# MKV31F51212 register map
Vendor: Freescale Semiconductor, Inc.; Series: Kinetis_V; File version: 1.6
CPU: CM4 r0p1, little endian, no MPU, FPU, VTOR, 4 interrupt priority bits
Registers are 32-bit, read-write, reset 0x0 unless marked. A register's access mark holds for its fields unless they carry their own. Offsets are from the block's base; [hi:lo] are bit positions; {n}, {i} and the like mark numbered series.

## PTA — General Purpose Input/Output
Base 0x400FF000; register names take the prefix GPIOA_
0x00 PDOR — Port Data Output Register
  [31:0] PDO — Port Data Output
    0=Logic level 0 is driven on pin, provided pin is configured for general-purpose output; 1=Logic level 1 is driven on pin, provided pin is configured for general-purpose output
0x04 PSOR wo — Port Set Output Register
  [31:0] PTSO — Port Set Output
    0=Corresponding bit in PDORn does not change; 1=Corresponding bit in PDORn is set to logic 1
0x08 PCOR wo — Port Clear Output Register
  [31:0] PTCO — Port Clear Output
    0=Corresponding bit in PDORn does not change; 1=Corresponding bit in PDORn is cleared to logic 0
0x0C PTOR wo — Port Toggle Output Register
  [31:0] PTTO — Port Toggle Output
    0=Corresponding bit in PDORn does not change; 1=Corresponding bit in PDORn is set to the inverse of its existing logic state
0x10 PDIR ro — Port Data Input Register
  [31:0] PDI — Port Data Input
    0=Pin logic level is logic 0, or is not configured for use by digital function; 1=Pin logic level is logic 1
0x14 PDDR — Port Data Direction Register
  [31:0] PDD — Port Data Direction
    0=Pin is configured as general-purpose input, for the GPIO function; 1=Pin is configured as general-purpose output, for the GPIO function

## PTB — General Purpose Input/Output
Base 0x400FF040; register names take the prefix GPIOB_
Registers as PTA.

## PTC — General Purpose Input/Output
Base 0x400FF080; register names take the prefix GPIOC_
Registers as PTA; these are added or differ:
0x08 PCOR wo — Port Clear Output Register
  [31:0] PTCO — Port Clear Output
    0=Corresponding bit in PDORn does not change; 1=Corresponding bit in PDORn is cleared to logic 0

## PTD — General Purpose Input/Output
Base 0x400FF0C0; register names take the prefix GPIOD_
Registers as PTA.

## PTE — General Purpose Input/Output
Base 0x400FF100; register names take the prefix GPIOE_
Registers as PTA.

## SysTick — System timer
Base 0xE000E010; register names take the prefix SYST_
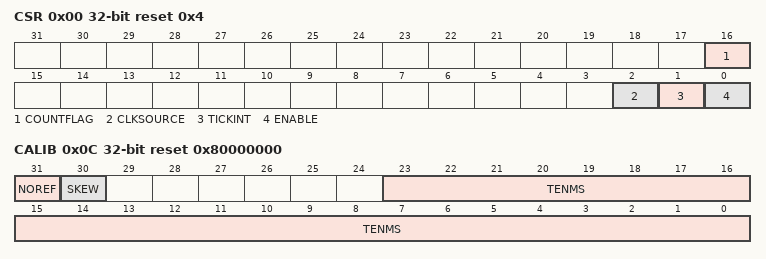
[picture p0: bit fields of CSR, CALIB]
0x00 CSR reset 0x4 — SysTick Control and Status Register
  [16] COUNTFLAG
  [2] CLKSOURCE
    0=external clock; 1=processor clock
  [1] TICKINT
    0=counting down to 0 does not assert the SysTick exception request; 1=counting down to 0 asserts the SysTick exception request
  [0] ENABLE
    0=counter disabled; 1=counter enabled
0x04 RVR — SysTick Reload Value Register
  [23:0] RELOAD — Value to load into the SysTick Current Value Register when the counter reaches 0
0x08 CVR — SysTick Current Value Register
  [23:0] CURRENT — Current value at the time the register is accessed
0x0C CALIB ro reset 0x80000000 — SysTick Calibration Value Register
  [31] NOREF
    0=The reference clock is provided; 1=The reference clock is not provided
  [30] SKEW
    0=10ms calibration value is exact; 1=10ms calibration value is inexact, because of the clock frequency
  [23:0] TENMS — Reload value to use for 10ms timing

## NVIC — Nested Vectored Interrupt Controller
Base 0xE000E100
{0x0+4i} NVICISER{i} (i=0..3) — Interrupt Set Enable Register n
  [31:0] SETENA — Interrupt set enable bits
{0x80+4i} NVICICER{i} (i=0..3) — Interrupt Clear Enable Register n
  [31:0] CLRENA — Interrupt clear-enable bits
{0x100+4i} NVICISPR{i} (i=0..3) — Interrupt Set Pending Register n
  [31:0] SETPEND — Interrupt set-pending bits
{0x180+4i} NVICICPR{i} (i=0..3) — Interrupt Clear Pending Register n
  [31:0] CLRPEND — Interrupt clear-pending bits
{0x200+4i} NVICIABR{i} (i=0..3) — Interrupt Active bit Register n
  [31:0] ACTIVE — Interrupt active flags
{0x300+i} NVICIP{i} 8-bit (i=0..105) — Interrupt Priority Register n
  [7:0] PRI{i} — Priority of interrupt {i}
0xE00 NVICSTIR — Software Trigger Interrupt Register
  [8:0] INTID — Interrupt ID of the interrupt to trigger, in the range 0-239. For example, a value of 0x03 specifies interrupt IRQ3.

## MCM — Core Platform Miscellaneous Control Module
Base 0xE0080000; register names take the prefix MCM_
0x08 PLASC 16-bit ro reset 0x1F — Crossbar Switch (AXBS) Slave Configuration
  [7:0] ASC — Each bit in the ASC field indicates whether there is a corresponding connection to the crossbar switch's slave input port.
    0=A bus slave connection to AXBS input port n is absent; 1=A bus slave connection to AXBS input port n is present
0x0A PLAMC 16-bit ro reset 0x17 — Crossbar Switch (AXBS) Master Configuration
  [7:0] AMC — Each bit in the AMC field indicates whether there is a corresponding connection to the AXBS master input port.
    0=A bus master connection to AXBS input port n is absent; 1=A bus master connection to AXBS input port n is present
0x0C PLACR — Crossbar Switch (AXBS) Control Register
  [9] ARB — Arbitration select
    0=Fixed-priority arbitration for the crossbar masters; 1=Round-robin arbitration for the crossbar masters
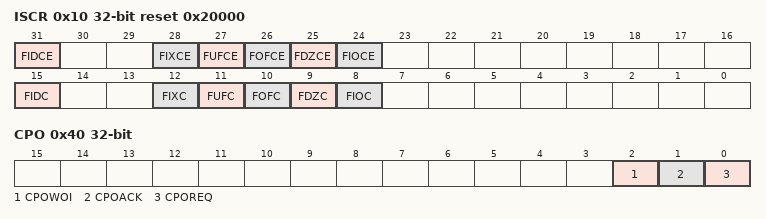
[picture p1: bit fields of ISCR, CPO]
0x10 ISCR reset 0x20000 — Interrupt Status and Control Register
  [31] FIDCE — FPU input denormal interrupt enable
    0=Disable interrupt; 1=Enable interrupt
  [28] FIXCE — FPU inexact interrupt enable
    0=Disable interrupt; 1=Enable interrupt
  [27] FUFCE — FPU underflow interrupt enable
    0=Disable interrupt; 1=Enable interrupt
  [26] FOFCE — FPU overflow interrupt enable
    0=Disable interrupt; 1=Enable interrupt
  [25] FDZCE — FPU divide-by-zero interrupt enable
    0=Disable interrupt; 1=Enable interrupt
  [24] FIOCE — FPU invalid operation interrupt enable
    0=Disable interrupt; 1=Enable interrupt
  [15] FIDC ro — FPU input denormal interrupt status
    0=No interrupt; 1=Interrupt occurred
  [12] FIXC ro — FPU inexact interrupt status
    0=No interrupt; 1=Interrupt occurred
  [11] FUFC ro — FPU underflow interrupt status
    0=No interrupt; 1=Interrupt occurred
  [10] FOFC ro — FPU overflow interrupt status
    0=No interrupt; 1=Interrupt occurred
  [9] FDZC ro — FPU divide-by-zero interrupt status
    0=No interrupt; 1=Interrupt occurred
  [8] FIOC ro — FPU invalid operation interrupt status
    0=No interrupt; 1=Interrupt occurred
0x40 CPO — Compute Operation Control Register
  [2] CPOWOI — Compute Operation wakeup on interrupt
    0=No effect; 1=When set, the CPOREQ is cleared on any interrupt or exception vector fetch
  [1] CPOACK ro — Compute Operation acknowledge
    0=Compute operation entry has not completed or compute operation exit has completed; 1=Compute operation entry has completed or compute operation exit has not completed
  [0] CPOREQ — Compute Operation request
    0=Request is cleared; 1=Request Compute Operation
